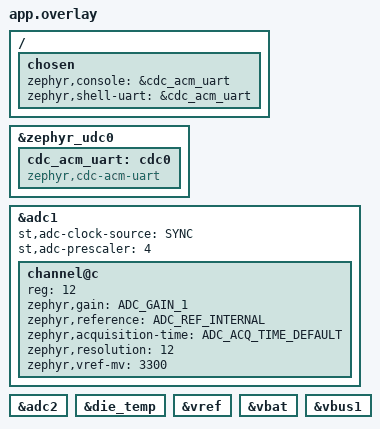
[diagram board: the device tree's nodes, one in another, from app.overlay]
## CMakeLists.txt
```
# Copyright (c) 2024 Panoramix Labs
# SPDX-License-Identifier: Apache-2.0

cmake_minimum_required(VERSION 3.13.1)
find_package(Zephyr REQUIRED HINTS $ENV{ZEPHYR_BASE})

project(app LANGUAGES C)

target_sources(app PRIVATE src/main.c)
```

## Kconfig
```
# Copyright (c) 2024 Panoramix Labs
# SPDX-License-Identifier: Apache-2.0

source "Kconfig.zephyr"

module = APP
module-str = APP
source "subsys/logging/Kconfig.template.log_config"
```

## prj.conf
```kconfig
# Copyright (c) 2024 Panoramix Labs
# SPDX-License-Identifier: Apache-2.0

CONFIG_LOG=y
CONFIG_STDOUT_CONSOLE=y
CONFIG_APP_LOG_LEVEL_DBG=y
CONFIG_USB_DRIVER_LOG_LEVEL_ERR=y
CONFIG_USB_DEVICE_LOG_LEVEL_ERR=y

CONFIG_USB_DEVICE_STACK=y
CONFIG_USB_DEVICE_INITIALIZE_AT_BOOT=n
CONFIG_USB_DEVICE_STACK=y
CONFIG_USB_DEVICE_PRODUCT="Fwbox Shell"
CONFIG_USB_DEVICE_VID=0x1209
CONFIG_USB_DEVICE_PID=0x0001

CONFIG_SERIAL=y
CONFIG_UART_INTERRUPT_DRIVEN=y
CONFIG_UART_LINE_CTRL=y

CONFIG_SHELL=y

CONFIG_GPIO=y
CONFIG_GPIO_SHELL=y

CONFIG_I2C=y
CONFIG_I2C_SHELL=y

CONFIG_ADC=y
CONFIG_ADC_SHELL=y

CONFIG_SENSOR=y
CONFIG_SENSOR_SHELL=y

CONFIG_LED=y
CONFIG_LED_SHELL=y
```

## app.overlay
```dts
/*
 * Copyright (c) 2024 Panoramix Labs
 *
 * SPDX-License-Identifier: Apache-2.0
 */

/ {
	chosen {
		zephyr,console = &cdc_acm_uart;
		zephyr,shell-uart = &cdc_acm_uart;
	};
};

&zephyr_udc0 {
	status = "okay";

	cdc_acm_uart: cdc0 {
		compatible = "zephyr,cdc-acm-uart";
	};
};

&adc1 {
	status = "okay";
	st,adc-clock-source = <SYNC>;
	st,adc-prescaler = <4>;

	#address-cells = <1>;
	#size-cells = <0>;

	channel@c {
		reg = <12>;
		zephyr,gain = "ADC_GAIN_1";
		zephyr,reference = "ADC_REF_INTERNAL";
		zephyr,acquisition-time = <ADC_ACQ_TIME_DEFAULT>;
		zephyr,resolution = <12>;
		zephyr,vref-mv = <3300>;
	};
};

&adc2 {
	status = "okay";
};

&die_temp {
	status = "okay";
};

&vref {
	status = "okay";
};

&vbat {
	status = "okay";
};

&vbus1 {
	status = "okay";
};
```

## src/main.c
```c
/*
 * Copyright (c) 2019 Intel Corporation
 *
 * SPDX-License-Identifier: Apache-2.0
 */

/**
 * @file
 * @brief Sample echo app for CDC ACM class
 *
 * Sample app for USB CDC ACM class driver. The received data is echoed back
 * to the serial port.
 */

#include <stdio.h>
#include <string.h>
#include <zephyr/device.h>
#include <zephyr/drivers/uart.h>
#include <zephyr/kernel.h>
#include <zephyr/sys/ring_buffer.h>

#include <zephyr/usb/usb_device.h>
#include <zephyr/usb/usbd.h>
#include <zephyr/logging/log.h>
LOG_MODULE_REGISTER(cdc_acm_echo, LOG_LEVEL_INF);

const struct device *const uart_dev = DEVICE_DT_GET_ONE(zephyr_cdc_acm_uart);

int main(void)
{
	int ret;

	if (!device_is_ready(uart_dev)) {
		LOG_ERR("CDC ACM device not ready");
		return 0;
	}

	ret = usb_enable(NULL);
	if (ret != 0) {
		LOG_ERR("Failed to enable USB");
		return 0;
	}

	return 0;
}
```
